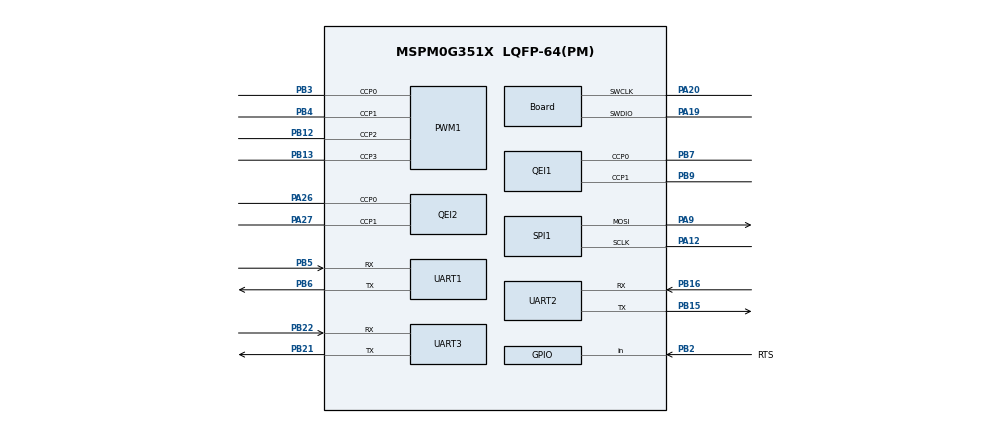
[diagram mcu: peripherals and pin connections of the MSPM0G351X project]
/**
 *
 * @cliArgs --device "MSPM0G351X" --part "Default" --package "LQFP-64(PM)" --product "mspm0_sdk@2.11.00.07"
 * @versions {"tool":"1.28.0+4712"}
 */

/**
 * Import the modules used in this configuration.
 */
const ADC12  = scripting.addModule("/ti/driverlib/ADC12", {}, false);
const ADC121 = ADC12.addInstance();
const GPIO   = scripting.addModule("/ti/driverlib/GPIO", {}, false);
const GPIO1  = GPIO.addInstance();
const GPIO2  = GPIO.addInstance();
const GPIO3  = GPIO.addInstance();
const GPIO4  = GPIO.addInstance();
const GPIO5  = GPIO.addInstance();
const PWM    = scripting.addModule("/ti/driverlib/PWM", {}, false);
const PWM1   = PWM.addInstance();
const QEI    = scripting.addModule("/ti/driverlib/QEI", {}, false);
const QEI1   = QEI.addInstance();
const QEI2   = QEI.addInstance();
const SPI    = scripting.addModule("/ti/driverlib/SPI", {}, false);
const SPI1   = SPI.addInstance();
const SYSCTL = scripting.addModule("/ti/driverlib/SYSCTL");
const TIMER  = scripting.addModule("/ti/driverlib/TIMER", {}, false);
const TIMER1 = TIMER.addInstance();
const TIMER2 = TIMER.addInstance();
const UART   = scripting.addModule("/ti/driverlib/UART", {}, false);
const UART1  = UART.addInstance();
const UART2  = UART.addInstance();
const UART3  = UART.addInstance();

/**
 * Write custom configuration values to the imported modules.
 */
const divider6       = system.clockTree["PLL_CLK2X_DIV"];
divider6.divideValue = 4;

const divider7       = system.clockTree["PLL_PDIV"];
divider7.divideValue = 2;

const divider9       = system.clockTree["UDIV"];
divider9.divideValue = 2;

const multiplier2         = system.clockTree["PLL_QDIV"];
multiplier2.multiplyValue = 10;

const mux8       = system.clockTree["HSCLKMUX"];
mux8.inputSelect = "HSCLKMUX_SYSPLL2X";

ADC121.enableDMA                  = false;
ADC121.$name                      = "ADC_Tracking";
ADC121.adcMem0chansel             = "DL_ADC12_INPUT_CHAN_4";
ADC121.sampClkDiv                 = "DL_ADC12_CLOCK_DIVIDE_8";
ADC121.powerDownMode              = "DL_ADC12_POWER_DOWN_MODE_MANUAL";
ADC121.sampleTime0                = "10us";
ADC121.peripheral.$assign         = "ADC0";
ADC121.peripheral.adcPin4.$assign = "PB25";
ADC121.adcPin4Config.$name        = "ti_driverlib_gpio_GPIOPinGeneric12";

const Board                       = scripting.addModule("/ti/driverlib/Board", {}, false);
Board.peripheral.$assign          = "DEBUGSS";
Board.peripheral.swclkPin.$assign = "PA20";
Board.peripheral.swdioPin.$assign = "PA19";

GPIO1.$name                              = "BUTTON";
GPIO1.associatedPins.create(4);
GPIO1.associatedPins[0].$name            = "SW2";
GPIO1.associatedPins[0].assignedPort     = "PORTB";
GPIO1.associatedPins[0].direction        = "INPUT";
GPIO1.associatedPins[0].internalResistor = "PULL_UP";
GPIO1.associatedPins[0].assignedPin      = "0";
GPIO1.associatedPins[1].$name            = "SW3";
GPIO1.associatedPins[1].direction        = "INPUT";
GPIO1.associatedPins[1].assignedPort     = "PORTB";
GPIO1.associatedPins[1].assignedPin      = "1";
GPIO1.associatedPins[1].internalResistor = "PULL_UP";
GPIO1.associatedPins[2].$name            = "SW4";
GPIO1.associatedPins[2].direction        = "INPUT";
GPIO1.associatedPins[2].assignedPort     = "PORTA";
GPIO1.associatedPins[2].assignedPin      = "30";
GPIO1.associatedPins[2].internalResistor = "PULL_UP";
GPIO1.associatedPins[3].$name            = "SW5";
GPIO1.associatedPins[3].direction        = "INPUT";
GPIO1.associatedPins[3].internalResistor = "PULL_UP";
GPIO1.associatedPins[3].assignedPort     = "PORTA";
GPIO1.associatedPins[3].assignedPin      = "31";

GPIO2.$name                              = "WIRELESS_CTRL";
GPIO2.associatedPins[0].$name            = "RTS";
GPIO2.associatedPins[0].direction        = "INPUT";
GPIO2.associatedPins[0].internalResistor = "PULL_UP";
GPIO2.associatedPins[0].assignedPort     = "PORTB";
GPIO2.associatedPins[0].assignedPin      = "2";
GPIO2.associatedPins[0].pin.$assign      = "PB2";

GPIO3.$name                          = "BUZZER";
GPIO3.associatedPins[0].$name        = "CTL";
GPIO3.associatedPins[0].assignedPort = "PORTA";
GPIO3.associatedPins[0].assignedPin  = "18";

GPIO4.$name                          = "GRAY_MUX";
GPIO4.associatedPins.create(4);
GPIO4.associatedPins[0].$name        = "S0";
GPIO4.associatedPins[0].assignedPort = "PORTB";
GPIO4.associatedPins[0].assignedPin  = "17";
GPIO4.associatedPins[1].$name        = "S1";
GPIO4.associatedPins[1].assignedPort = "PORTB";
GPIO4.associatedPins[1].assignedPin  = "18";
GPIO4.associatedPins[2].$name        = "S2";
GPIO4.associatedPins[2].assignedPort = "PORTB";
GPIO4.associatedPins[2].assignedPin  = "20";
GPIO4.associatedPins[3].$name        = "S3";
GPIO4.associatedPins[3].assignedPort = "PORTB";
GPIO4.associatedPins[3].assignedPin  = "19";

GPIO5.$name                          = "IPS200_CTRL";
GPIO5.associatedPins.create(4);
GPIO5.associatedPins[0].$name        = "RST";
GPIO5.associatedPins[0].assignedPort = "PORTA";
GPIO5.associatedPins[0].assignedPin  = "7";
GPIO5.associatedPins[0].initialValue = "SET";
GPIO5.associatedPins[1].$name        = "CS";
GPIO5.associatedPins[1].initialValue = "SET";
GPIO5.associatedPins[1].assignedPort = "PORTA";
GPIO5.associatedPins[1].assignedPin  = "8";
GPIO5.associatedPins[2].$name        = "BLK";
GPIO5.associatedPins[2].assignedPort = "PORTA";
GPIO5.associatedPins[2].assignedPin  = "13";
GPIO5.associatedPins[3].$name        = "DC";
GPIO5.associatedPins[3].initialValue = "SET";
GPIO5.associatedPins[3].assignedPort = "PORTA";
GPIO5.associatedPins[3].assignedPin  = "15";

PWM1.$name                              = "MOTOR_PWM";
PWM1.timerCount                         = 4000;
PWM1.pwmMode                            = "EDGE_ALIGN_UP";
PWM1.ccIndex                            = [0,1,2,3];
PWM1.PWM_CHANNEL_0.$name                = "ti_driverlib_pwm_PWMTimerCC0";
PWM1.PWM_CHANNEL_1.$name                = "ti_driverlib_pwm_PWMTimerCC1";
PWM1.ccp0PinConfig.direction            = scripting.forceWrite("OUTPUT");
PWM1.ccp0PinConfig.hideOutputInversion  = scripting.forceWrite(false);
PWM1.ccp0PinConfig.onlyInternalResistor = scripting.forceWrite(false);
PWM1.ccp0PinConfig.passedPeripheralType = scripting.forceWrite("Digital");
PWM1.ccp0PinConfig.$name                = "ti_driverlib_gpio_GPIOPinGeneric2";
PWM1.ccp1PinConfig.direction            = scripting.forceWrite("OUTPUT");
PWM1.ccp1PinConfig.hideOutputInversion  = scripting.forceWrite(false);
PWM1.ccp1PinConfig.onlyInternalResistor = scripting.forceWrite(false);
PWM1.ccp1PinConfig.passedPeripheralType = scripting.forceWrite("Digital");
PWM1.ccp1PinConfig.$name                = "ti_driverlib_gpio_GPIOPinGeneric3";
PWM1.peripheral.$assign                 = "TIMA0";
PWM1.peripheral.ccp0Pin.$assign         = "PB3";
PWM1.peripheral.ccp1Pin.$assign         = "PB4";
PWM1.peripheral.ccp2Pin.$assign         = "PB12";
PWM1.peripheral.ccp3Pin.$assign         = "PB13";
PWM1.PWM_CHANNEL_2.$name                = "ti_driverlib_pwm_PWMTimerCC2";
PWM1.PWM_CHANNEL_3.$name                = "ti_driverlib_pwm_PWMTimerCC3";
PWM1.ccp2PinConfig.$name                = "ti_driverlib_gpio_GPIOPinGeneric10";
PWM1.ccp3PinConfig.$name                = "ti_driverlib_gpio_GPIOPinGeneric11";

QEI1.$name                              = "QEI_LEFT";
QEI1.peripheral.ccp0Pin.$assign         = "PB7";
QEI1.peripheral.ccp1Pin.$assign         = "PB9";
QEI1.ccp0PinConfig.hideOutputInversion  = scripting.forceWrite(false);
QEI1.ccp0PinConfig.onlyInternalResistor = scripting.forceWrite(false);
QEI1.ccp0PinConfig.passedPeripheralType = scripting.forceWrite("Digital");
QEI1.ccp0PinConfig.$name                = "ti_driverlib_gpio_GPIOPinGeneric0";
QEI1.ccp1PinConfig.hideOutputInversion  = scripting.forceWrite(false);
QEI1.ccp1PinConfig.onlyInternalResistor = scripting.forceWrite(false);
QEI1.ccp1PinConfig.passedPeripheralType = scripting.forceWrite("Digital");
QEI1.ccp1PinConfig.$name                = "ti_driverlib_gpio_GPIOPinGeneric1";

QEI2.$name                              = "QEI_RIGHT";
QEI2.peripheral.$assign                 = "TIMG8";
QEI2.peripheral.ccp0Pin.$assign         = "PA26";
QEI2.peripheral.ccp1Pin.$assign         = "PA27";
QEI2.ccp0PinConfig.hideOutputInversion  = scripting.forceWrite(false);
QEI2.ccp0PinConfig.onlyInternalResistor = scripting.forceWrite(false);
QEI2.ccp0PinConfig.passedPeripheralType = scripting.forceWrite("Digital");
QEI2.ccp0PinConfig.$name                = "ti_driverlib_gpio_GPIOPinGeneric6";
QEI2.ccp1PinConfig.hideOutputInversion  = scripting.forceWrite(false);
QEI2.ccp1PinConfig.onlyInternalResistor = scripting.forceWrite(false);
QEI2.ccp1PinConfig.passedPeripheralType = scripting.forceWrite("Digital");
QEI2.ccp1PinConfig.$name                = "ti_driverlib_gpio_GPIOPinGeneric7";

SPI1.$name                              = "IPS200_SPI";
SPI1.targetBitRate                      = 20000000;
SPI1.frameFormat                        = "MOTO3";
SPI1.direction                          = "PICO";
SPI1.sclkPinConfig.direction            = scripting.forceWrite("OUTPUT");
SPI1.sclkPinConfig.onlyInternalResistor = scripting.forceWrite(false);
SPI1.sclkPinConfig.passedPeripheralType = scripting.forceWrite("Digital");
SPI1.sclkPinConfig.$name                = "ti_driverlib_gpio_GPIOPinGeneric13";
SPI1.mosiPinConfig.direction            = scripting.forceWrite("OUTPUT");
SPI1.mosiPinConfig.hideOutputInversion  = scripting.forceWrite(false);
SPI1.mosiPinConfig.onlyInternalResistor = scripting.forceWrite(false);
SPI1.mosiPinConfig.passedPeripheralType = scripting.forceWrite("Digital");
SPI1.mosiPinConfig.$name                = "ti_driverlib_gpio_GPIOPinGeneric14";
SPI1.peripheral.sclkPin.$assign         = "PA12";
SPI1.peripheral.mosiPin.$assign         = "PA9";

SYSCTL.forceDefaultClkConfig = true;
SYSCTL.clockTreeEn           = true;

TIMER1.timerClkPrescale   = 256;
TIMER1.timerPeriod        = "10 ms";
TIMER1.interrupts         = ["ZERO"];
TIMER1.timerMode          = "PERIODIC";
TIMER1.interruptPriority  = "1";
TIMER1.$name              = "TIMER_G0";
TIMER1.peripheral.$assign = "TIMG0";

TIMER2.$name              = "TIMER_G7";
TIMER2.timerClkPrescale   = 256;
TIMER2.interrupts         = ["ZERO"];
TIMER2.timerMode          = "PERIODIC_UP";
TIMER2.timerPeriod        = "20 ms";
TIMER2.interruptPriority  = "3";
TIMER2.peripheral.$assign = "TIMG7";

UART1.enableFIFO                       = true;
UART1.rxFifoThreshold                  = "DL_UART_RX_FIFO_LEVEL_ONE_ENTRY";
UART1.txFifoThreshold                  = "DL_UART_TX_FIFO_LEVEL_EMPTY";
UART1.targetBaudRate                   = 115200;
UART1.$name                            = "WIRELESS_UART";
UART1.peripheral.$assign               = "UART1";
UART1.peripheral.rxPin.$assign         = "PB5";
UART1.peripheral.txPin.$assign         = "PB6";
UART1.txPinConfig.direction            = scripting.forceWrite("OUTPUT");
UART1.txPinConfig.hideOutputInversion  = scripting.forceWrite(false);
UART1.txPinConfig.onlyInternalResistor = scripting.forceWrite(false);
UART1.txPinConfig.passedPeripheralType = scripting.forceWrite("Digital");
UART1.txPinConfig.$name                = "ti_driverlib_gpio_GPIOPinGeneric4";
UART1.rxPinConfig.hideOutputInversion  = scripting.forceWrite(false);
UART1.rxPinConfig.onlyInternalResistor = scripting.forceWrite(false);
UART1.rxPinConfig.passedPeripheralType = scripting.forceWrite("Digital");
UART1.rxPinConfig.$name                = "ti_driverlib_gpio_GPIOPinGeneric5";

UART2.$name                            = "GYRO_UART";
UART2.targetBaudRate                   = 115200;
UART2.enableFIFO                       = true;
UART2.rxFifoThreshold                  = "DL_UART_RX_FIFO_LEVEL_ONE_ENTRY";
UART2.txFifoThreshold                  = "DL_UART_TX_FIFO_LEVEL_EMPTY";
UART2.peripheral.$assign               = "UART7";
UART2.peripheral.rxPin.$assign         = "PB16";
UART2.peripheral.txPin.$assign         = "PB15";
UART2.txPinConfig.direction            = scripting.forceWrite("OUTPUT");
UART2.txPinConfig.hideOutputInversion  = scripting.forceWrite(false);
UART2.txPinConfig.onlyInternalResistor = scripting.forceWrite(false);
UART2.txPinConfig.passedPeripheralType = scripting.forceWrite("Digital");
UART2.txPinConfig.$name                = "ti_driverlib_gpio_GPIOPinGeneric8";
UART2.rxPinConfig.hideOutputInversion  = scripting.forceWrite(false);
UART2.rxPinConfig.onlyInternalResistor = scripting.forceWrite(false);
UART2.rxPinConfig.passedPeripheralType = scripting.forceWrite("Digital");
UART2.rxPinConfig.$name                = "ti_driverlib_gpio_GPIOPinGeneric9";

UART3.$name                            = "TASK_UART";
UART3.targetBaudRate                   = 115200;
UART3.enableFIFO                       = true;
UART3.rxFifoThreshold                  = "DL_UART_RX_FIFO_LEVEL_ONE_ENTRY";
UART3.txFifoThreshold                  = "DL_UART_TX_FIFO_LEVEL_EMPTY";
UART3.uartClkDiv                       = "2";
UART3.peripheral.$assign               = "UART4";
UART3.peripheral.rxPin.$assign         = "PB22";
UART3.peripheral.txPin.$assign         = "PB21";
UART3.txPinConfig.$name                = "ti_driverlib_gpio_GPIOPinGeneric15";
UART3.txPinConfig.direction            = scripting.forceWrite("OUTPUT");
UART3.txPinConfig.hideOutputInversion  = scripting.forceWrite(false);
UART3.txPinConfig.onlyInternalResistor = scripting.forceWrite(false);
UART3.txPinConfig.passedPeripheralType = scripting.forceWrite("Digital");
UART3.rxPinConfig.$name                = "ti_driverlib_gpio_GPIOPinGeneric16";
UART3.rxPinConfig.hideOutputInversion  = scripting.forceWrite(false);
UART3.rxPinConfig.onlyInternalResistor = scripting.forceWrite(false);
UART3.rxPinConfig.passedPeripheralType = scripting.forceWrite("Digital");

const ProjectConfig              = scripting.addModule("/ti/project_config/ProjectConfig", {}, false);
ProjectConfig.migrationCondition = true;

/**
 * Pinmux solution for unlocked pins/peripherals. This ensures that minor changes to the automatic solver in a future
 * version of the tool will not impact the pinmux you originally saw.  These lines can be completely deleted in order to
 * re-solve from scratch.
 */
GPIO1.associatedPins[0].pin.$suggestSolution = "PB0";
GPIO1.associatedPins[1].pin.$suggestSolution = "PB1";
GPIO1.associatedPins[2].pin.$suggestSolution = "PA30";
GPIO1.associatedPins[3].pin.$suggestSolution = "PA31";
GPIO3.associatedPins[0].pin.$suggestSolution = "PA18";
GPIO4.associatedPins[0].pin.$suggestSolution = "PB17";
GPIO4.associatedPins[1].pin.$suggestSolution = "PB18";
GPIO4.associatedPins[2].pin.$suggestSolution = "PB20";
GPIO4.associatedPins[3].pin.$suggestSolution = "PB19";
GPIO5.associatedPins[0].pin.$suggestSolution = "PA7";
GPIO5.associatedPins[1].pin.$suggestSolution = "PA8";
GPIO5.associatedPins[2].pin.$suggestSolution = "PA13";
GPIO5.associatedPins[3].pin.$suggestSolution = "PA15";
QEI1.peripheral.$suggestSolution             = "TIMG9";
SPI1.peripheral.$suggestSolution             = "SPI0";
